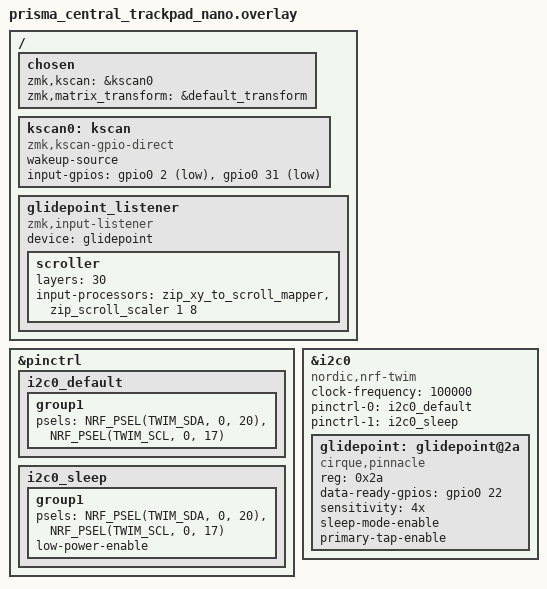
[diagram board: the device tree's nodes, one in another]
/*
 * Cirque I2C breakout: SDA D3/P0.20, SCL D2/P0.17, power and ground through FFC.
 * Separate direct DR wire D4/P0.22; keys D19/P0.02 and D21/P0.31.
 *
 * SPDX-License-Identifier: MIT
 */

#include <zephyr/dt-bindings/input/input-event-codes.h>
#include <input/processors.dtsi>
#include "prisma_pointing_transform.dtsi"

/ {
    chosen {
        zmk,kscan = &kscan0;
        zmk,matrix_transform = &default_transform;
    };

    kscan0: kscan {
        compatible = "zmk,kscan-gpio-direct";
        wakeup-source;
        input-gpios
            = <&gpio0 2 (GPIO_ACTIVE_LOW | GPIO_PULL_UP)>
            , <&gpio0 31 (GPIO_ACTIVE_LOW | GPIO_PULL_UP)>
            ;
    };

    glidepoint_listener: glidepoint_listener {
        compatible = "zmk,input-listener";
        device = <&glidepoint>;

        /* layer 30 (the right key held): the pad scrolls */
        scroller {
            layers = <30>;
            input-processors = <&zip_xy_to_scroll_mapper>, <&zip_scroll_scaler 1 8>;
        };
    };
};

&pinctrl {
    i2c0_default: i2c0_default {
        group1 {
            psels = <NRF_PSEL(TWIM_SDA, 0, 20)>,
                    <NRF_PSEL(TWIM_SCL, 0, 17)>;
        };
    };

    i2c0_sleep: i2c0_sleep {
        group1 {
            psels = <NRF_PSEL(TWIM_SDA, 0, 20)>,
                    <NRF_PSEL(TWIM_SCL, 0, 17)>;
            low-power-enable;
        };
    };
};

&i2c0 {
    status = "okay";
    compatible = "nordic,nrf-twim";
    clock-frequency = <100000>;
    pinctrl-0 = <&i2c0_default>;
    pinctrl-1 = <&i2c0_sleep>;
    pinctrl-names = "default", "sleep";

    glidepoint: glidepoint@2a {
        compatible = "cirque,pinnacle";
        reg = <0x2a>;
        status = "okay";
        data-ready-gpios = <&gpio0 22 GPIO_ACTIVE_HIGH>;
        sensitivity = "4x";
        sleep-mode-enable;
        primary-tap-enable;
        /* Validate orientation and tap/sleep behaviour on the actual pad. */
    };
};
